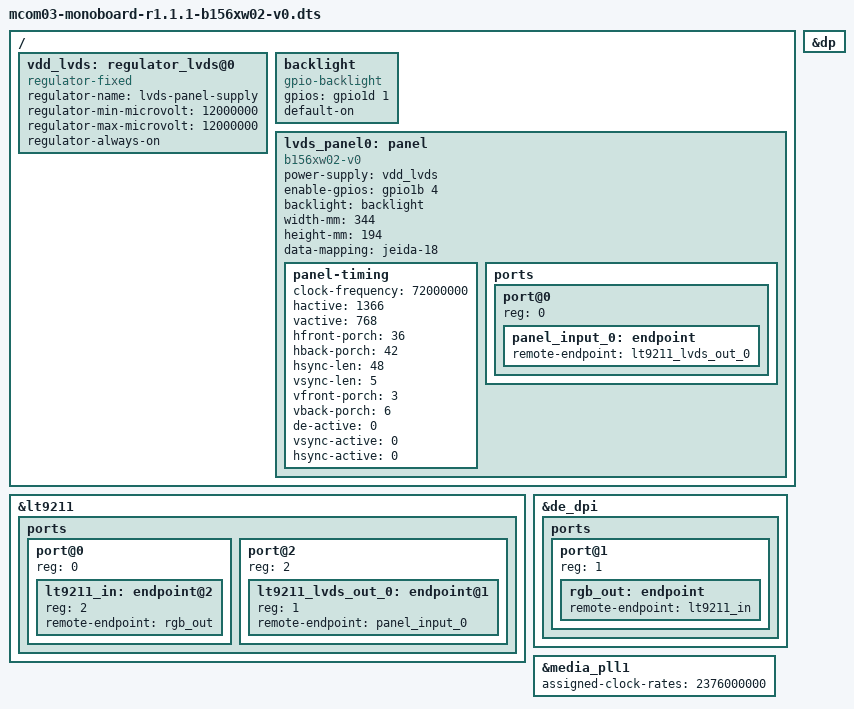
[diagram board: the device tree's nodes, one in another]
// SPDX-License-Identifier: GPL-2.0+
/*
 * Copyright 2024 RnD Center "ELVEES", JSC
 */

#include "mcom03-monoboard-r1.1.1.dts"

/ {
	vdd_lvds: regulator_lvds@0 {
		compatible = "regulator-fixed";
		regulator-name = "lvds-panel-supply";
		regulator-min-microvolt = <12000000>;
		regulator-max-microvolt = <12000000>;
		regulator-always-on;
	};

	backlight: backlight {
		compatible = "gpio-backlight";
		gpios = <&gpio1d 1 GPIO_ACTIVE_HIGH>; // BL_PWM signal
		default-on;
	};

	lvds_panel0: panel {
		compatible = "b156xw02-v0", "panel-lvds";

		power-supply = <&vdd_lvds>;

		enable-gpios = <&gpio1b 4 GPIO_ACTIVE_HIGH>; // BL_ON signal
		backlight = <&backlight>;

		width-mm = <344>;
		height-mm = <194>;

		data-mapping = "jeida-18";

		panel-timing {
			clock-frequency = <72000000>;

			// From b156xw02-v0 EDID
			hactive = <1366>;
			vactive = <768>;

			hfront-porch = <36>;
			hback-porch = <42>;
			hsync-len = <48>;
			vsync-len = <5>;
			vfront-porch = <3>;
			vback-porch = <6>;

			de-active = <0>;
			vsync-active = <0>;
			hsync-active = <0>;
		};

		ports {
			#address-cells = <1>;
			#size-cells = <0>;

			port@0 {
				reg = <0>;

				panel_input_0: endpoint {
						remote-endpoint = <&lt9211_lvds_out_0>;
				};
			};
		};
	};
};

&lt9211 {
	status = "okay";

	ports {
		#address-cells = <1>;
		#size-cells = <0>;

		// rgb
		port@0 {
			#address-cells = <1>;
			#size-cells = <0>;
			reg = <0>;

			lt9211_in: endpoint@2 {
				reg = <2>;
				remote-endpoint = <&rgb_out>;
			};
		};

		// lvds-out
		port@2 {
			#address-cells = <1>;
			#size-cells = <0>;
			reg = <2>;

			lt9211_lvds_out_0: endpoint@1 {
				reg = <1>;
				remote-endpoint = <&panel_input_0>;
			};
		};
	};
};

&dp {
	status = "okay";
};

&de_dpi {
	status = "okay";

	ports {
		port@1 {
			reg = <1>;

			rgb_out: endpoint {
				remote-endpoint = <&lt9211_in>;
			};
		};
	};
};

// For fine pixel clocks
&media_pll1 {
	assigned-clock-rates = <2376000000>;
};
